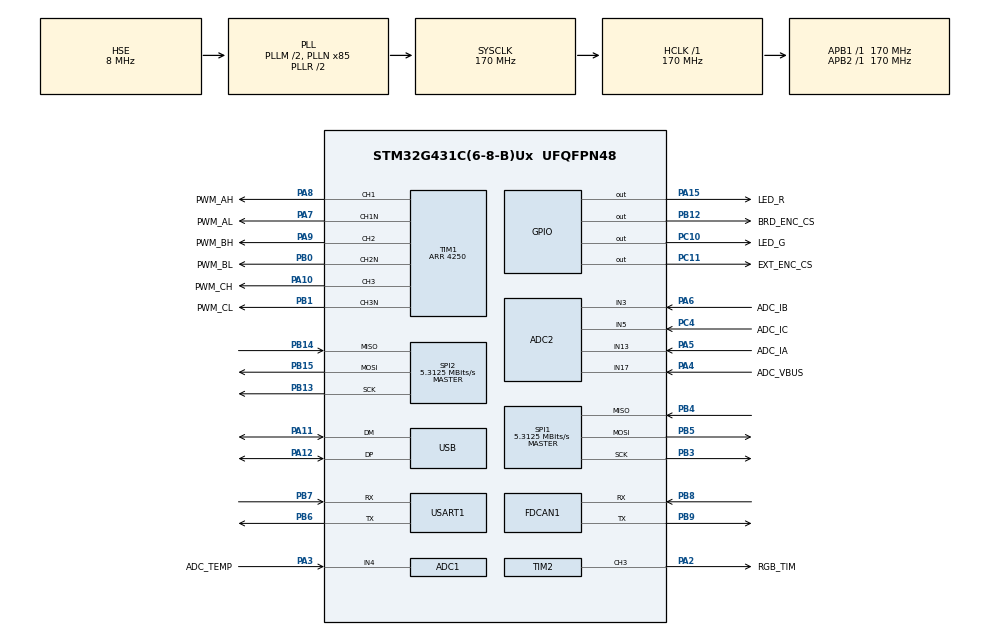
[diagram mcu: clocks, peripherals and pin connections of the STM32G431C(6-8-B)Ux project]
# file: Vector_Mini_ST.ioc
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ADC1.Channel-0\#ChannelRegularConversion=ADC_CHANNEL_4
ADC1.EnableInjectedConversion=ENABLE
ADC1.ExternalTrigInjecConv=ADC_EXTERNALTRIGINJEC_T1_CC4
ADC1.ExternalTrigInjecConvEdge=ADC_EXTERNALTRIGINJECCONV_EDGE_FALLING
ADC1.InjNumberOfConversion=1
ADC1.InjectedChannel-1\#ChannelInjectedConversion=ADC_CHANNEL_4
ADC1.InjectedOffsetNumber-1\#ChannelInjectedConversion=ADC_OFFSET_NONE
ADC1.InjectedRank-1\#ChannelInjectedConversion=1
ADC1.InjectedSamplingTime-1\#ChannelInjectedConversion=ADC_SAMPLETIME_2CYCLES_5
ADC1.NbrOfConversionFlag=1
ADC1.OffsetNumber-0\#ChannelRegularConversion=ADC_OFFSET_NONE
ADC1.Rank-0\#ChannelRegularConversion=1
ADC1.Rank1_Channel=ADC_CHANNEL_4
ADC1.SamplingTime-0\#ChannelRegularConversion=ADC_SAMPLETIME_2CYCLES_5
ADC1.master=1
ADC2.ContinuousConvMode=DISABLE
ADC2.EnableInjectedConversion=ENABLE
ADC2.EnableInjectedOversampling=DISABLE
ADC2.EnableRegularConversion=DISABLE
ADC2.ExternalTrigInjecConv=ADC_EXTERNALTRIGINJEC_T1_CC4
ADC2.ExternalTrigInjecConvEdge=ADC_EXTERNALTRIGINJECCONV_EDGE_FALLING
ADC2.InjNumberOfConversion=4
ADC2.InjectedChannel-1\#ChannelInjectedConversion=ADC_CHANNEL_13
ADC2.InjectedChannel-2\#ChannelInjectedConversion=ADC_CHANNEL_3
ADC2.InjectedChannel-3\#ChannelInjectedConversion=ADC_CHANNEL_5
ADC2.InjectedChannel-4\#ChannelInjectedConversion=ADC_CHANNEL_17
ADC2.InjectedOffsetNumber-1\#ChannelInjectedConversion=ADC_OFFSET_NONE
ADC2.InjectedOffsetNumber-2\#ChannelInjectedConversion=ADC_OFFSET_NONE
ADC2.InjectedOffsetNumber-3\#ChannelInjectedConversion=ADC_OFFSET_NONE
ADC2.InjectedOffsetNumber-4\#ChannelInjectedConversion=ADC_OFFSET_NONE
ADC2.InjectedRank-1\#ChannelInjectedConversion=1
ADC2.InjectedRank-2\#ChannelInjectedConversion=2
ADC2.InjectedRank-3\#ChannelInjectedConversion=3
ADC2.InjectedRank-4\#ChannelInjectedConversion=4
ADC2.InjectedSamplingTime-1\#ChannelInjectedConversion=ADC_SAMPLETIME_6CYCLES_5
ADC2.InjectedSamplingTime-2\#ChannelInjectedConversion=ADC_SAMPLETIME_6CYCLES_5
ADC2.InjectedSamplingTime-3\#ChannelInjectedConversion=ADC_SAMPLETIME_6CYCLES_5
ADC2.InjectedSamplingTime-4\#ChannelInjectedConversion=ADC_SAMPLETIME_12CYCLES_5
Dma.Request0=TIM2_CH3
Dma.TIM2_CH3.0.Direction=DMA_MEMORY_TO_PERIPH
Dma.TIM2_CH3.0.EventEnable=DISABLE
Dma.TIM2_CH3.0.Instance=DMA1_Channel1
Dma.TIM2_CH3.0.MemDataAlignment=DMA_MDATAALIGN_HALFWORD
Dma.TIM2_CH3.0.MemInc=DMA_MINC_ENABLE
Dma.TIM2_CH3.0.Mode=DMA_NORMAL
Dma.TIM2_CH3.0.PeriphDataAlignment=DMA_PDATAALIGN_WORD
Dma.TIM2_CH3.0.PeriphInc=DMA_PINC_DISABLE
Dma.TIM2_CH3.0.Polarity=HAL_DMAMUX_REQ_GEN_RISING
Dma.TIM2_CH3.0.Priority=DMA_PRIORITY_LOW
Dma.TIM2_CH3.0.RequestNumber=1
Dma.TIM2_CH3.0.SignalID=NONE
Dma.TIM2_CH3.0.SyncEnable=DISABLE
Dma.TIM2_CH3.0.SyncPolarity=HAL_DMAMUX_SYNC_NO_EVENT
Dma.TIM2_CH3.0.SyncRequestNumber=1
Dma.TIM2_CH3.0.SyncSignalID=NONE
FDCAN1.AutoRetransmission=ENABLE
FDCAN1.CalculateBaudRateNominal=999999
FDCAN1.CalculateTimeBitNominal=1000
FDCAN1.CalculateTimeQuantumNominal=58.82352941176471
FDCAN1.DataPrescaler=10
FDCAN1.DataTimeSeg1=12
FDCAN1.DataTimeSeg2=4
FDCAN1.ExtFiltersNbr=0
FDCAN1.FrameFormat=FDCAN_FRAME_FD_BRS
FDCAN1.NominalPrescaler=10
FDCAN1.NominalTimeSeg1=12
FDCAN1.NominalTimeSeg2=4
FDCAN1.StdFiltersNbr=8
FDCAN1.TxFifoQueueMode=FDCAN_TX_QUEUE_OPERATION
Mcu.Family=STM32G4
Mcu.Name=STM32G431C(6-8-B)Ux
Mcu.Package=UFQFPN48
NVIC.ADC1_2_IRQn=true\:0\:0\:false\:false\:true\:true\:true\:true
NVIC.DMA1_Channel1_IRQn=true\:5\:0\:true\:false\:true\:false\:true\:true
NVIC.FDCAN1_IT0_IRQn=true\:1\:0\:true\:false\:true\:true\:true\:true
NVIC.PriorityGroup=NVIC_PRIORITYGROUP_4
NVIC.TIM7_IRQn=true\:3\:0\:true\:false\:true\:true\:true\:true
NVIC.USB_HP_IRQn=true\:2\:0\:true\:false\:true\:true\:true\:true
NVIC.USB_LP_IRQn=true\:2\:0\:true\:false\:true\:false\:true\:true
PA10.GPIO_Label=PWM_CH
PA10.Signal=S_TIM1_CH3
PA10.Stacked=true
PA11.Mode=Device
PA11.Signal=USB_DM
PA11.Stacked=true
PA12.Mode=Device
PA12.Signal=USB_DP
PA12.Stacked=true
PA13.Mode=Serial_Wire
PA13.Signal=SYS_JTMS-SWDIO
PA14.Mode=Serial_Wire
PA14.Signal=SYS_JTCK-SWCLK
PA15.GPIO_Label=LED_R
PA15.GPIO_PuPd=GPIO_PULLUP
PA15.GPIO_Speed=GPIO_SPEED_FREQ_VERY_HIGH
PA15.PinState=GPIO_PIN_SET
PA15.Signal=GPIO_Output
PA2.GPIO_Label=RGB_TIM
PA2.Signal=S_TIM2_CH3
PA2.Stacked=true
PA3.GPIO_Label=ADC_TEMP
PA3.Mode=IN4-Single-Ended
PA3.Signal=ADC1_IN4
PA3.Stacked=true
PA4.GPIO_Label=ADC_VBUS
PA4.Mode=IN17-Single-Ended
PA4.Signal=ADC2_IN17
PA4.Stacked=true
PA5.GPIO_Label=ADC_IA
PA5.Mode=IN13-Single-Ended
PA5.Signal=ADC2_IN13
PA5.Stacked=true
PA6.GPIO_Label=ADC_IB
PA6.Mode=IN3-Single-Ended
PA6.Signal=ADC2_IN3
PA6.Stacked=true
PA7.GPIO_Label=PWM_AL
PA7.Mode=PWM Generation1 CH1 CH1N
PA7.Signal=TIM1_CH1N
PA7.Stacked=true
PA8.GPIO_Label=PWM_AH
PA8.Signal=S_TIM1_CH1
PA8.Stacked=true
PA9.GPIO_Label=PWM_BH
PA9.Signal=S_TIM1_CH2
PA9.Stacked=true
PB0.GPIO_Label=PWM_BL
PB0.Mode=PWM Generation2 CH2 CH2N
PB0.Signal=TIM1_CH2N
PB0.Stacked=true
PB1.GPIO_Label=PWM_CL
PB1.Mode=PWM Generation3 CH3 CH3N
PB1.Signal=TIM1_CH3N
PB1.Stacked=true
PB12.GPIO_Label=BRD_ENC_CS
PB12.GPIO_PuPd=GPIO_PULLUP
PB12.GPIO_Speed=GPIO_SPEED_FREQ_VERY_HIGH
PB12.PinState=GPIO_PIN_SET
PB12.Signal=GPIO_Output
PB12.Stacked=true
PB13.Mode=Full_Duplex_Master
PB13.Signal=SPI2_SCK
PB13.Stacked=true
PB14.Mode=Full_Duplex_Master
PB14.Signal=SPI2_MISO
PB14.Stacked=true
PB15.Mode=Full_Duplex_Master
PB15.Signal=SPI2_MOSI
PB15.Stacked=true
PB3.Mode=Full_Duplex_Master
PB3.Signal=SPI1_SCK
PB3.Stacked=true
PB4.Mode=Full_Duplex_Master
PB4.Signal=SPI1_MISO
PB4.Stacked=true
PB5.Mode=Full_Duplex_Master
PB5.Signal=SPI1_MOSI
PB5.Stacked=true
PB6.Mode=Asynchronous
PB6.Signal=USART1_TX
PB6.Stacked=true
PB7.Mode=Asynchronous
PB7.Signal=USART1_RX
PB7.Stacked=true
PB8-BOOT0.Mode=FDCAN_Activate
PB8-BOOT0.Signal=FDCAN1_RX
PB8-BOOT0.Stacked=true
PB9.Mode=FDCAN_Activate
PB9.Signal=FDCAN1_TX
PB9.Stacked=true
PC10.GPIO_Label=LED_G
PC10.GPIO_PuPd=GPIO_PULLUP
PC10.GPIO_Speed=GPIO_SPEED_FREQ_VERY_HIGH
PC10.PinState=GPIO_PIN_SET
PC10.Signal=GPIO_Output
PC11.GPIO_Label=EXT_ENC_CS
PC11.GPIO_PuPd=GPIO_PULLUP
PC11.GPIO_Speed=GPIO_SPEED_FREQ_VERY_HIGH
PC11.PinState=GPIO_PIN_SET
PC11.Signal=GPIO_Output
PC11.Stacked=true
PC4.GPIO_Label=ADC_IC
PC4.Mode=IN5-Single-Ended
PC4.Signal=ADC2_IN5
PC4.Stacked=true
PF0-OSC_IN.Mode=HSE-External-Oscillator
PF0-OSC_IN.Signal=RCC_OSC_IN
PF1-OSC_OUT.Mode=HSE-External-Oscillator
PF1-OSC_OUT.Signal=RCC_OSC_OUT
ProjectManager.HeapSize=0x200
ProjectManager.StackSize=0x400
ProjectManager.TargetToolchain=MDK-ARM V5.32
RCC.ADC12Freq_Value=170000000
RCC.AHBFreq_Value=170000000
RCC.APB1Freq_Value=170000000
RCC.APB1TimFreq_Value=170000000
RCC.APB2Freq_Value=170000000
RCC.APB2TimFreq_Value=170000000
RCC.CK48CLockSelection=RCC_USBCLKSOURCE_HSI48
RCC.CortexFreq_Value=170000000
RCC.EXTERNAL_CLOCK_VALUE=12288000
RCC.HCLKFreq_Value=170000000
RCC.HSE_VALUE=8000000
RCC.HSI48_VALUE=48000000
RCC.HSI_VALUE=16000000
RCC.LSE_VALUE=32768
RCC.PLLM=RCC_PLLM_DIV2
RCC.PLLN=85
RCC.PLLSourceVirtual=RCC_PLLSOURCE_HSE
RCC.SYSCLKFreq_VALUE=170000000
RCC.SYSCLKSource=RCC_SYSCLKSOURCE_PLLCLK
RCC.USBFreq_Value=48000000
RCC.VCOOutputFreq_Value=340000000
SH.S_TIM1_CH1.0=TIM1_CH1,PWM Generation1 CH1 CH1N
SH.S_TIM1_CH2.0=TIM1_CH2,PWM Generation2 CH2 CH2N
SH.S_TIM1_CH3.0=TIM1_CH3,PWM Generation3 CH3 CH3N
SH.S_TIM2_CH3.0=TIM2_CH3,PWM Generation3 CH3
SPI1.BaudRatePrescaler=SPI_BAUDRATEPRESCALER_32
SPI1.CLKPhase=SPI_PHASE_2EDGE
SPI1.CalculateBaudRate=5.3125 MBits/s
SPI1.DataSize=SPI_DATASIZE_16BIT
SPI1.Direction=SPI_DIRECTION_2LINES
SPI1.Mode=SPI_MODE_MASTER
SPI1.VirtualType=VM_MASTER
SPI2.BaudRatePrescaler=SPI_BAUDRATEPRESCALER_32
SPI2.CLKPhase=SPI_PHASE_2EDGE
SPI2.CRCCalculation=SPI_CRCCALCULATION_DISABLE
SPI2.CalculateBaudRate=5.3125 MBits/s
SPI2.DataSize=SPI_DATASIZE_16BIT
SPI2.Direction=SPI_DIRECTION_2LINES
SPI2.Mode=SPI_MODE_MASTER
SPI2.VirtualType=VM_MASTER
TIM1.AutoReloadPreload=TIM_AUTORELOAD_PRELOAD_ENABLE
TIM1.Channel-PWM\ Generation1\ CH1\ CH1N=TIM_CHANNEL_1
TIM1.Channel-PWM\ Generation2\ CH2\ CH2N=TIM_CHANNEL_2
TIM1.Channel-PWM\ Generation3\ CH3\ CH3N=TIM_CHANNEL_3
TIM1.Channel-PWM\ Generation4\ No\ Output=TIM_CHANNEL_4
TIM1.CounterMode=TIM_COUNTERMODE_CENTERALIGNED1
TIM1.DeadTime=0
TIM1.Dithering=Disable
TIM1.PeriodNoDither=4250
TIM1.PulseNoDither_1=4250
TIM1.PulseNoDither_2=4250
TIM1.PulseNoDither_3=4250
TIM1.PulseNoDither_4=4240
TIM2.Channel-PWM\ Generation3\ CH3=TIM_CHANNEL_3
TIM2.PeriodNoDither=212-1
TIM2.Prescaler=1-1
TIM7.AutoReloadPreload=TIM_AUTORELOAD_PRELOAD_ENABLE
TIM7.PeriodNoDither=1000-1
TIM7.Prescaler=170-1
TIM7.TIM_MasterOutputTrigger=TIM_TRGO_ENABLE
USART1.VirtualMode-Asynchronous=VM_ASYNC
USB_DEVICE.CLASS_NAME_FS=CDC
USB_DEVICE.VirtualMode=Cdc
USB_DEVICE.VirtualModeFS=Cdc_FS
VP_SYS_VS_DBSignals.Mode=DisableDeadBatterySignals
VP_TIM1_VS_ClockSourceINT.Mode=Internal
VP_TIM1_VS_no_output4.Mode=PWM Generation4 No Output
VP_TIM2_VS_ClockSourceINT.Mode=Internal
VP_TIM7_VS_ClockSourceINT.Mode=Enable_Timer
VP_USB_DEVICE_VS_USB_DEVICE_CDC_FS.Mode=CDC_FS
board=custom

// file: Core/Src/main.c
/* USER CODE BEGIN Header */
/**
  ******************************************************************************
  * @file           : main.c
  * @brief          : Main program body
  ******************************************************************************
  * @attention
  *
  * Copyright (c) 2025 STMicroelectronics.
  * All rights reserved.
  *
  * This software is licensed under terms that can be found in the LICENSE file
  * in the root directory of this software component.
  * If no LICENSE file comes with this software, it is provided AS-IS.
  *
  ******************************************************************************
  */
/* USER CODE END Header */
#include "main.h"
#include "adc.h"
#include "dma.h"
#include "fdcan.h"
#include "spi.h"
#include "tim.h"
#include "usart.h"
#include "gpio.h"

/* USER CODE BEGIN Includes */
#include "common_inc.h"
#include "SEGGER_RTT.h"
/* USER CODE END Includes */

void SystemClock_Config(void);

int main(void)
{

  /* MCU Configuration--------------------------------------------------------*/

  /* Reset of all peripherals, Initializes the Flash interface and the Systick. */
  HAL_Init();

  /* USER CODE BEGIN Init */
    SEGGER_RTT_ConfigUpBuffer(1, "JScope_i2i2i2i2i2i2i2i2i2i2i2i2", bRttBuf, sizeof(bRttBuf), SEGGER_RTT_MODE_NO_BLOCK_SKIP);

  /* USER CODE END Init */

  /* Configure the system clock */
  SystemClock_Config();

  /* Initialize all configured peripherals */
  MX_GPIO_Init();
  MX_DMA_Init();
  MX_ADC2_Init();
  MX_FDCAN1_Init();
  MX_TIM1_Init();
  MX_TIM2_Init();
  MX_TIM7_Init();
  MX_ADC1_Init();
  MX_SPI1_Init();
  MX_SPI2_Init();
  MX_USART1_UART_Init();
  /* USER CODE BEGIN 2 */
  Board_Init();
  /* USER CODE END 2 */

  /* Infinite loop */
  while (1)
  {

    /* USER CODE BEGIN 3 */
	CAN_SendMessage();

	if(Get_ModeNow() == Save_Param)
	{
		/*disable global interrupt*/
		__disable_irq();
		/*write parameters to flash*/
		flash_write_param();
		/*enable global interrupt*/
		__enable_irq();

		Set_ModeNow(Motor_Disable);
	}
  }
  /* USER CODE END 3 */
}

void SystemClock_Config(void)
{
  RCC_OscInitTypeDef RCC_OscInitStruct = {0};
  RCC_ClkInitTypeDef RCC_ClkInitStruct = {0};

  /** Configure the main internal regulator output voltage
  */
  HAL_PWREx_ControlVoltageScaling(PWR_REGULATOR_VOLTAGE_SCALE1_BOOST);

  /** Initializes the RCC Oscillators according to the specified parameters
  * in the RCC_OscInitTypeDef structure.
  */
  RCC_OscInitStruct.OscillatorType = RCC_OSCILLATORTYPE_HSI48|RCC_OSCILLATORTYPE_HSE;
  RCC_OscInitStruct.HSEState = RCC_HSE_ON;
  RCC_OscInitStruct.HSI48State = RCC_HSI48_ON;
  RCC_OscInitStruct.PLL.PLLState = RCC_PLL_ON;
  RCC_OscInitStruct.PLL.PLLSource = RCC_PLLSOURCE_HSE;
  RCC_OscInitStruct.PLL.PLLM = RCC_PLLM_DIV2;
  RCC_OscInitStruct.PLL.PLLN = 85;
  RCC_OscInitStruct.PLL.PLLP = RCC_PLLP_DIV2;
  RCC_OscInitStruct.PLL.PLLQ = RCC_PLLQ_DIV2;
  RCC_OscInitStruct.PLL.PLLR = RCC_PLLR_DIV2;
  if (HAL_RCC_OscConfig(&RCC_OscInitStruct) != HAL_OK)
  {
    Error_Handler();
  }

  /** Initializes the CPU, AHB and APB buses clocks
  */
  RCC_ClkInitStruct.ClockType = RCC_CLOCKTYPE_HCLK|RCC_CLOCKTYPE_SYSCLK
                              |RCC_CLOCKTYPE_PCLK1|RCC_CLOCKTYPE_PCLK2;
  RCC_ClkInitStruct.SYSCLKSource = RCC_SYSCLKSOURCE_PLLCLK;
  RCC_ClkInitStruct.AHBCLKDivider = RCC_SYSCLK_DIV1;
  RCC_ClkInitStruct.APB1CLKDivider = RCC_HCLK_DIV1;
  RCC_ClkInitStruct.APB2CLKDivider = RCC_HCLK_DIV1;

  if (HAL_RCC_ClockConfig(&RCC_ClkInitStruct, FLASH_LATENCY_4) != HAL_OK)
  {
    Error_Handler();
  }
}

void Error_Handler(void)
{
  __disable_irq();
  while (1)
  {
  }
}
